# RFBI register map
Vendor: Texas Instruments
Peripheral module from a debugger description file (folder omap5430_ES2_PUBLIC).
Registers are 32-bit, access per field, reset 0x0 unless marked. A register's access mark holds for its fields unless they carry their own. Offsets are as the file gives them; lines under a group give offsets from that group; [hi:lo] are bit positions; {n}, {i} and the like mark numbered series; 'fields as' and 'values as' point back to an identical list; <NAME> marks a mode.

## RFBI
0x00 RFBI_REVISION ro reset not defined — This register contains the IP revision.
  [31:0] REVISION — IP revision
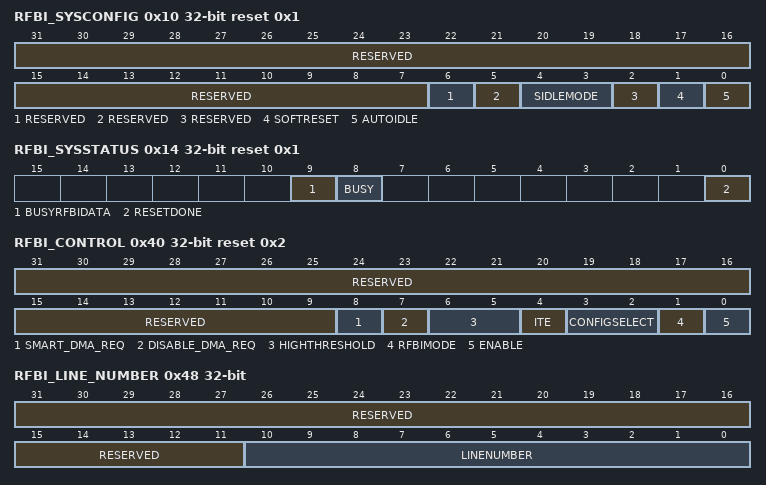
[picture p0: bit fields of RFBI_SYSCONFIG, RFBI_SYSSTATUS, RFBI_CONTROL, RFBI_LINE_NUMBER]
0x10 RFBI_SYSCONFIG reset 0x1 — This register controls various parameters of the slave port interface.
  [31:7] RESERVED ro — Write 0s for future compatibility. Reads return 0.
  [6] RESERVED ro — Write 0s for future compatibility. Reads return 0.
  [5] RESERVED ro — Write 0s for future compatibility. Reads return 0.
  [4:3] SIDLEMODE rw — Slave interface power management, idle req/ack control
    0=Force-idle. An idle request is acknowledged unconditionally.; 1=No-idle. An idle request is never acknowledged.; 2=Smart-idle. Acknowledgment to an idle request is given based on the internal activity of the module.
  [2] RESERVED ro — Write 0s for future compatibility. Reads return 0.
  [1] SOFTRESET rw — Software reset Sets this bit to 1 to trigger a module reset. The bit is automatically reset by the hardware. During reads, it always returns 0.
    0=NormalMode; 1=ResetDone (The module is reset.)
  [0] AUTOIDLE rw — Internal clock gating strategy (RFBI_ICLK clock and DISPC clock)
    0=Freerunning (RFBI_ICLK clock and DISPC clock are free-running); 1=Gating (Automatic clock gating strategy is applied for the RFBI_ICLK clock and DISPC clock, based on the slave port interface and internal activity.)
0x14 RFBI_SYSSTATUS ro reset 0x1 — This register provides status information about the module, excluding interrupt status information.
  [9] BUSYRFBIDATA — Data are pending to be processed from interconnect FIFO.
    0=NothingPending (No data pending); 1=PendingData (Some data pending)
  [8] BUSY — Slave port busy status bit
    0=NoStall (Access to the following register is not stalled:, , , .); 1=Stall (Access to any of the following registers is stalled:, , , .)
  [0] RESETDONE — Internal reset monitoring. It can be used to determine when a hardware reset is complete or when a software reset is complete (software has setRFBI_SYSCONFIG[0] SOFTRESET to 1).
    0=ongoing (Internal module reset ongoing); 1=Completed (Reset completed)
0x40 RFBI_CONTROL reset 0x2 — The register configures the RFBI module.
  [31:9] RESERVED ro — Write 0s for future compatibility. Reads return 0.
  [8] SMART_DMA_REQ rw — Smart DMA request
    0=Disable (The dmareq is asserted and deasserted depending on FIFO space, even if MIdlereq is high in smart-idle/no-idle mode and the entire burst gets error responses from the module.); 1=Enable (The dmareq is deasserted after 2 clock cycles, if it has been asserted for more than or equal to 2 clock cycles and MIdlereq is high in smart-idle or no-idle mode. No more burst requests are given, even if the space is available in the FIFO.)
  [7] DISABLE_DMA_REQ rw — Disable DMA request.
    0=Enable (The dmareq is enabled and the signal is generated based on the space available and the request coming into the data register.); 1=Disable (The dmareq is disabled and the signal is not generated at all based on space in FIFO. It stays high until the DISABLE DM AREQ is high even if there is space in FIFO to take requests.)
  [6:5] HIGHTHRESHOLD rw — Defines the FIFO high threshold used by hardware to assert DMA request. Used only if data written toRFBI_DATA are sent using sDMA.
    0=f4x32 (Size of the transfer of 4 words of 32 bits wide); 1=f8x32 (Size of the transfer of 8 words of 32 bits wide); 2=f16x32 (Size of the transfer of 16 words of 32 bits wide)
  [4] ITE rw — Internal trigger
    0=Reset (Hardware waits for the ITE bit to be set if in internal trigger mode for the configuration in use.); 1=Set (User sets the ITE bit to start the transfer. When hardware takes into account the bit, the hardware resets it.)
  [3:2] CONFIGSELECT rw — Select the CS and configuration.
    0=NoCSSelected; 1=CS0Selected; 2=CS1Selected (Reserved); 3=CS0andCSi1Selected (Reserved)
  [1] RFBIMODE rw
    0=The_RFBI_mode_is_selected; 1=The_RFBI_mode_is_not_selected
  [0] ENABLE rw — Enable/disable flag
    0=Disable the RFBI module; 1=Enable the RFBI module
0x44 RFBI_PIXEL_CNT rw — The register configures the RFBI pixel count value.
  [31:0] PIXELCNT — Pixel counter value The software indicates the number of pixels to transfer to the LCD panel frame buffer. The value is set when the module is disabled. During the transfer the hardware decrements the register when a pixel is sent to the RFB.
0x48 RFBI_LINE_NUMBER — The register configures the number of lines to synchronize the beginning of the transfer.
  [31:11] RESERVED ro — Write 0s for future compatibility. Reads return 0.
  [10:0] LINENUMBER rw — Programmable line number Line number from 0 to 2047. Number of HSYNC after the VSYNC occurs before the beginning of the transfer.
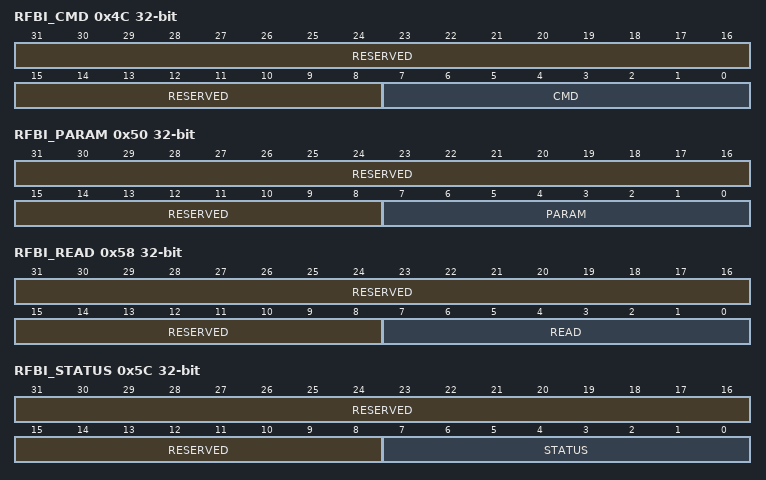
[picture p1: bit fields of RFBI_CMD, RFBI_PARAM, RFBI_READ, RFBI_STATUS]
0x4C RFBI_CMD — The register configures the RFBI command.
  [31:8] RESERVED ro — Write 0s for future compatibility. Reads return 0.
  [7:0] CMD wo — Command Value 8/9/12/16 bit value depending on the parallelMode [7:0] 8-bit DataType [8:0] 9-bit DataType [11:0] 12-bit DataType [15:0] 16-bit DataType
0x50 RFBI_PARAM — The register configures the RFBI parameter.
  [31:8] RESERVED ro — Write 0s for future compatibility. Reads return 0.
  [7:0] PARAM wo — Parameter value 8/9/12/16 bit value depending on the parallelMode [7:0] 8-bit DataType [8:0] 9-bit DataType [11:0] 12-bit DataType [15:0] 16-bit DataType
0x54 RFBI_DATA wo — The register configures the RFBI data.
  [31:0] DATA — Data value 12/16/18/24/2x16 bit value depending on: DataType [11:0] 12-bit DataType [15:0] 16-bit DataType [17:0] 18-bit DataType [23:0] 24-bit DataType [31:0] 2x16-bit
0x58 RFBI_READ — The register configures the RFBI read.
  [31:8] RESERVED ro — Write 0s for future compatibility. Reads return 0.
  [7:0] READ rw — Read value 8/9/12/16 bit value depending on the parallelMode [7:0] 8-bit DataType [8:0] 9-bit DataType [11:0] 12-bit DataType [15:0] 16-bit DataType
0x5C RFBI_STATUS — The register configures the RFBI status.
  [31:8] RESERVED ro — Write 0s for future compatibility. Reads return 0.
  [7:0] STATUS rw — Status value 8/9/12/16 bit value depending on the parallelMode [7:0] 8-bit DataType [8:0] 9-bit DataType [11:0] 12-bit DataType [15:0] 16-bit DataType
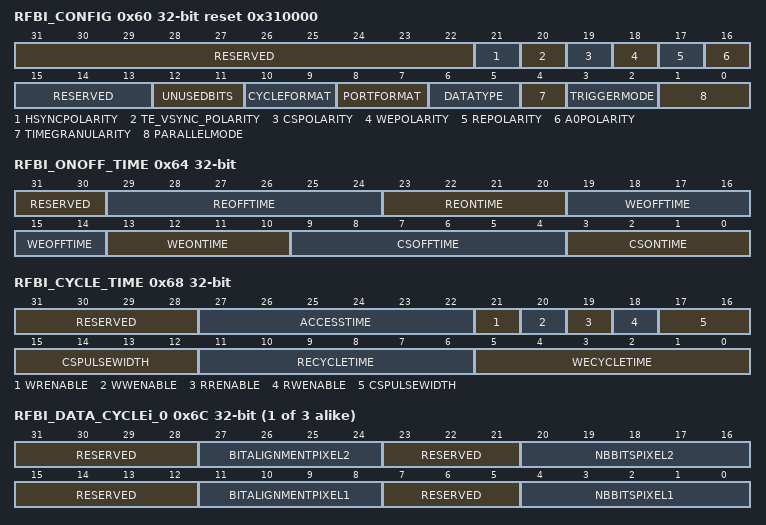
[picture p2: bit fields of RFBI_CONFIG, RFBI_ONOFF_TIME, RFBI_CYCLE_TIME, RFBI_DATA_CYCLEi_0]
0x60 RFBI_CONFIG reset 0x310000 — The control register sets the configuration for the LCD 0, LCD 1, and LCD 2.
  [31:22] RESERVED ro — Write 0s for future compatibility. Reads return 0.
  [21] HSYNCPOLARITY rw
    0=HSYNC_active_low; 1=HSYNC_active_high
  [20] TE_VSYNC_POLARITY rw — TE or VSYNC polarity
    0=active_low; 1=active_high
  [19] CSPOLARITY rw
    0=CS_active_low; 1=CS_active_high
  [18] WEPOLARITY rw
    0=Active_low; 1=Active_high
  [17] REPOLARITY rw
    0=Active_low; 1=Active_high
  [16] A0POLARITY rw
    0=A0_active_low; 1=A0_active_high
  [15:13] RESERVED ro — Write 0s for future compatibility. Reads return 0.
  [12:11] UNUSEDBITS rw — State of unused bits
    0=Low_level_(0); 1=High_level_(1); 2=Unchanged_from_previous_state
  [10:9] CYCLEFORMAT rw
    0=1_cycle_for_1_pixel; 1=2_cycles_for_1_pixel; 2=3_cycles_for_1_pixel; 3=3_cycles_for_2_pixels
  [8:7] PORTFORMAT rw — Slave port write access format
    0=1 pixel per slave port access to the register data; 2=2 pixels per slave port access to the register data with first pixel at the position [15:0]; 3=2 pixels per slave port access to the register data with first pixel at the position [31:16]
  [6:5] DATATYPE rw — Data type from the DISPC and slave port
    0=12-bit; 1=16-bit; 2=18-bit; 3=24-bit
  [4] TIMEGRANULARITY rw — Multiplies signal timing latencies by 2
    0=x2_latencies_disabled; 1=x2_latencies_enabled
  [3:2] TRIGGERMODE rw
    0=00_Internal_trigger_mode_(ITE_bit_mode); 1=External trigger mode (Tearing Effect Signal, rfbi_tevsync0 with programmable line counter defined in register); 2=External trigger mode (rfbi_tevsync0/rfbi_hsync0 with programmable line counter defined in register)
  [1:0] PARALLELMODE rw
    0=8-bit parallel output interface selected; 1=9-bit parallel output interface selected; 2=12-bit parallel output interface selected; 3=16-bit parallel output interface selected
0x64 RFBI_ONOFF_TIME — The control register configures the RFBI timings for the LCD 0, LCD 1, and LCD 2.
  [31:30] RESERVED ro — Write 0s for future compatibility. Reads return 0.
  [29:24] REOFFTIME rw — Read enable deassertion time from start access time. Number of RFBI_ICLK cycles.
  [23:20] REONTIME rw — Read enable assertion time from start access time. Number of RFBI_ICLK cycles.
  [19:14] WEOFFTIME rw — Write enable deassertion time from start access time. Number of RFBI_ICLK cycles.
  [13:10] WEONTIME rw — Write enable assertion time from start access time. Number of RFBI_ICLK cycles.
  [9:4] CSOFFTIME rw — CS deassertion time from start access time Number of RFBI_ICLK cycles
  [3:0] CSONTIME rw — CS assertion time from start access time Number of RFBI_ICLK cycles
0x68 RFBI_CYCLE_TIME — The control register configures the RFBI timings for the LCD 0, LCD 1, and LCD 2.
  [31:28] RESERVED ro — Write 0s for future compatibility. Reads return 0.
  [27:22] ACCESSTIME rw — Access time number of RFBI_ICLK cycles
  [21] WRENABLE rw — Write-to-read pulse width enable (same CS)
    0=CSPULSEWIDTH_0 (CSPULSEWIDTH does not apply on write-to-read access.); 1=CSPULSEWIDTH_1 (CSPULSEWIDTH applies on write-to-read access.)
  [20] WWENABLE rw — Write-to-write pulse width enable (same CS)
    0=CSPULSEWIDTH_0 (CSPULSEWIDTH does not apply on write-to-write access.); 1=CSPULSEWIDTH_1 (CSPULSEWIDTH applies on write-to-write access.)
  [19] RRENABLE rw — Read-to-read pulse width enable (same CS)
    0=CSPULSEWIDTH_0 (CSPULSEWIDTH does not apply on read-to-read access.); 1=CSPULSEWIDTH_1 (CSPULSEWIDTH applies on read-to-read access.)
  [18] RWENABLE rw — Read-to-write pulse width enable (same CS): 0x0: CSPULSEWIDTH does not apply on read-to-write access. 0x1: CSPULSEWIDTH applies on read-to-write access.
  [17:12] CSPULSEWIDTH rw — CS pulse width number of RFBI_ICLK cycles
  [11:6] RECYCLETIME rw — RE cycle time number of RFBI_ICLK cycles
  [5:0] WECYCLETIME rw — WE cycle time number of RFBI_ICLK cycles
{0x6C+4i} RFBI_DATA_CYCLEi_{i} (i=0..2) — The control register configures the RFBI data format for the i cycle (i = 1 for first cycle, i = 2 for second cycle, i = 3 for third cycle).
  [31:28] RESERVED ro — Write 0s for future compatibility. Reads return 0.
  [27:24] BITALIGNMENTPIXEL2 rw — Alignment of the bits from pixel 2 on the output interface
  [23:21] RESERVED ro — Write 0s for future compatibility. Reads return 0.
  [20:16] NBBITSPIXEL2 rw — Number of bits from the pixel 2 (value from 0 to 16 bits). The values from 17 to 31 are invalid.
  [15:12] RESERVED ro — Write 0s for future compatibility. Reads return 0.
  [11:8] BITALIGNMENTPIXEL1 rw — Alignment of the bits from pixel 1 on the output interface
  [7:5] RESERVED ro — Write 0s for future compatibility. Reads return 0.
  [4:0] NBBITSPIXEL1 rw — Number of bits from the pixel 1 (value from 0 to 16 bits). The values from 17 to 31 are invalid.
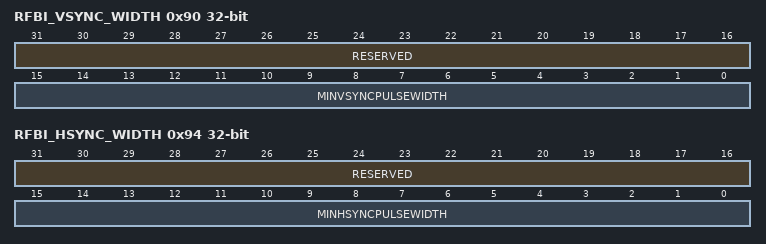
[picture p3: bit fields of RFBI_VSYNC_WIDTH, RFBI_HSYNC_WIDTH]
0x90 RFBI_VSYNC_WIDTH — The register configures the RFBI VSYNC minimum pulse width.
  [31:16] RESERVED ro — Write 0s for future compatibility. Reads return 0.
  [15:0] MINVSYNCPULSEWIDTH rw — Programmable minimum VSYNC pulse width. Minimum VSYNC pulse width from 0 to 65535. Number of RFBI_ICLK clock cycles to determine when VSYNC pulse occurs. The values 0 and 1 are invalid.
0x94 RFBI_HSYNC_WIDTH — The register configures the RFBI HSYNC minimum pulse width.
  [31:16] RESERVED ro — Write 0s for future compatibility. Reads return 0.
  [15:0] MINHSYNCPULSEWIDTH rw — Programmable minimum HSYNC pulse width. Minimum HSYNC pulse width from 0 to 65535. Number of RFBI_ICLK clock cycles to determine when HSYNC pulse occurs. The values 0 and 1 are invalid.
